# LPC176x5x register map
File version: 0.2
CPU: CM3 r0p0, little endian, no MPU, no FPU, 0x5 interrupt priority bits, 0x0 interrupts
Registers are 32-bit, read-write, no defined reset value unless marked. A register's access mark holds for its fields unless they carry their own. Offsets are from the block's base; [hi:lo] are bit positions.

## CANAF — CAN controller acceptance filter
Base 0x4003C000
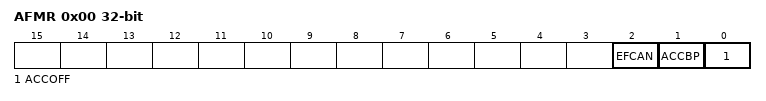
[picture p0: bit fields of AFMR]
0x00 AFMR — Acceptance Filter Register
  [2] EFCAN — FullCAN mode
    0=SOFTWARE_MUST_READ_A (Software must read all messages for all enabled IDs on all enabled CAN buses, from the receiving CAN controllers.); 1=THE_ACCEPTANCE_FILTE (The Acceptance Filter itself will take care of receiving and storing messages for selected Standard ID values on selected CAN buses. See Section 21.16 FullCAN mode on page 576.)
  [1] ACCBP — All Rx messages are accepted on enabled CAN controllers. Software must set this bit before modifying the contents of any of the registers described below, and before modifying the contents of Lookup Table RAM in any way other than setting or clearing Disable bits in Standard Identifier entries. When both this bit and AccOff are 0, the Acceptance filter operates to screen received CAN Identifiers.
  [0] ACCOFF — if AccBP is 0, the Acceptance Filter is not operational. All Rx messages on all CAN buses are ignored.
0x04 SFF_SA reset 0x0 — Standard Frame Individual Start Address Register
  [10:2] SFF_SA — The start address of the table of individual Standard Identifiers in AF Lookup RAM. If the table is empty, write the same value in this register and the SFF_GRP_sa register described below. For compatibility with possible future devices, write zeroes in bits 31:11 and 1:0 of this register. If the eFCAN bit in the AFMR is 1, this value also indicates the size of the table of Standard IDs which the Acceptance Filter will search and (if found) automatically store received messages in Acceptance Filter RAM.
0x08 SFF_GRP_SA reset 0x0 — Standard Frame Group Start Address Register
  [11:2] SFF_GRP_SA — The start address of the table of grouped Standard Identifiers in AF Lookup RAM. If the table is empty, write the same value in this register and the EFF_sa register described below. The largest value that should be written to this register is 0x800, when only the Standard Individual table is used, and the last word (address 0x7FC) in AF Lookup Table RAM is used. For compatibility with possible future devices, please write zeroes in bits 31:12 and 1:0 of this register.
0x0C EFF_SA reset 0x0 — Extended Frame Start Address Register
  [10:2] EFF_SA — The start address of the table of individual Extended Identifiers in AF Lookup RAM. If the table is empty, write the same value in this register and the EFF_GRP_sa register described below. The largest value that should be written to this register is 0x800, when both Extended Tables are empty and the last word (address 0x7FC) in AF Lookup Table RAM is used. For compatibility with possible future devices, please write zeroes in bits 31:11 and 1:0 of this register.
0x10 EFF_GRP_SA reset 0x0 — Extended Frame Group Start Address Register
  [11:2] EFF_GRP_SA — The start address of the table of grouped Extended Identifiers in AF Lookup RAM. If the table is empty, write the same value in this register and the ENDofTable register described below. The largest value that should be written to this register is 0x800, when this table is empty and the last word (address 0x7FC) in AF Lookup Table RAM is used. For compatibility with possible future devices, please write zeroes in bits 31:12 and 1:0 of this register.
0x14 ENDOFTABLE reset 0x0 — End of AF Tables register
  [11:2] ENDOFTABLE — The address above the last active address in the last active AF table. For compatibility with possible future devices, please write zeroes in bits 31:12 and 1:0 of this register. If the eFCAN bit in the AFMR is 0, the largest value that should be written to this register is 0x800, which allows the last word (address 0x7FC) in AF Lookup Table RAM to be used. If the eFCAN bit in the AFMR is 1, this value marks the start of the area of Acceptance Filter RAM, into which the Acceptance Filter will automatically receive messages for selected IDs on selected CAN buses. In this case, the maximum value that should be written to this register is 0x800 minus 6 times the value in SFF_sa. This allows 12 bytes of message storage between this address and the end of Acceptance Filter RAM, for each Standard ID that is specified between the start of Acceptance Filter RAM, and the next active AF table.
0x18 LUTERRAD ro reset 0x0 — LUT Error Address register
  [10:2] LUTERRAD — It the LUT Error bit (below) is 1, this read-only field contains the address in AF Lookup Table RAM, at which the Acceptance Filter encountered an error in the content of the tables.
0x1C LUTERR ro reset 0x0 — LUT Error Register
  [0] LUTERR — This read-only bit is set to 1 if the Acceptance Filter encounters an error in the content of the tables in AF RAM. It is cleared when software reads the LUTerrAd register. This condition is ORed with the other CAN interrupts from the CAN controllers, to produce the request that is connected to the NVIC.
0x20 FCANIE reset 0x0 — FullCAN interrupt enable register
  [0] FCANIE — Global FullCAN Interrupt Enable. When 1, this interrupt is enabled.
0x24 FCANIC0 reset 0x0 — FullCAN interrupt and capture register0
  [31:0] INTPND — FullCan Interrupt Pending 0 = FullCan Interrupt Pending bit 0. 1 = FullCan Interrupt Pending bit 1. ... 31 = FullCan Interrupt Pending bit 31.
0x28 FCANIC1 reset 0x0 — FullCAN interrupt and capture register1
  [31:0] IntPnd32 — FullCan Interrupt Pending bit 32. 0 = FullCan Interrupt Pending bit 32. 1 = FullCan Interrupt Pending bit 33. ... 31 = FullCan Interrupt Pending bit 63.
